# CC1350F128 register map
File version: 1.0
CPU: CM3 1.0, other endian, MPU, FPU, 3 interrupt priority bits
Registers are 32-bit, read-write, reset 0x0 unless marked. A register's access mark holds for its fields unless they carry their own. Offsets are from the block's base; [hi:lo] are bit positions; {n}, {i} and the like mark numbered series.

## AUX_ANAIF — AUX Analog Peripheral Control Module
Base 0x400C9000
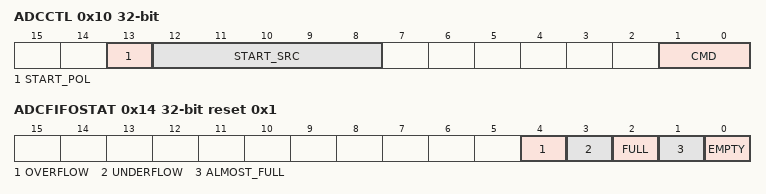
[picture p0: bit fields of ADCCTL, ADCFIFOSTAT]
0x10 ADCCTL — ADC Control Configuration of ADI_4_AUX:ADC0.SMPL_MODE decides if the ADC trigger starts sampling or conversion.
  [13] START_POL — [13:13] Select active polarity for START_SRC event.
    1=FALL (Set ADC trigger on falling edge of event source.); 0=RISE (Set ADC trigger on rising edge of event source.)
  [12:8] START_SRC — [12:8] Select ADC trigger event source from the asynchronous AUX event bus. Set START_SRC to NO_EVENT<n> if you want to trigger the ADC manually through ADCTRIG.START.
    31=ADC_IRQ (AUX_EVCTL:EVSTAT1.ADC_IRQ); 30=MCU_EV (AUX_EVCTL:EVSTAT1.MCU_EV); 29=ACLK_REF (AUX_EVCTL:EVSTAT1.ACLK_REF); {v}=AUXIO{v-13} (AUX_EVCTL:EVSTAT1.AUXIO{v-13}) (v=16..28); 15=AUXIO2 (AUX_EVCTL:EVSTAT0.AUXIO2); 14=AUXIO1 (AUX_EVCTL:EVSTAT0.AUXIO1); 13=AUXIO0 (AUX_EVCTL:EVSTAT0.AUXIO0); 12=AON_PROG_WU (AUX_EVCTL:EVSTAT0.AON_PROG_WU); 11=AON_SW (AUX_EVCTL:EVSTAT0.AON_SW); 10=NO_EVENT1; 9=NO_EVENT0; 6=SMPH_AUTOTAKE_DONE (AUX_EVCTL:EVSTAT0.SMPH_AUTOTAKE_DONE); 5=TIMER1_EV (AUX_EVCTL:EVSTAT0.TIMER1_EV); 4=TIMER0_EV (AUX_EVCTL:EVSTAT0.TIMER0_EV); 3=TDC_DONE (AUX_EVCTL:EVSTAT0.TDC_DONE); 2=AUX_COMPB (AUX_EVCTL:EVSTAT0.AUX_COMPB); 1=AUX_COMPA (AUX_EVCTL:EVSTAT0.AUX_COMPA); 0=RTC_CH2_EV (AUX_EVCTL:EVSTAT0.AON_RTC_CH2)
  [1:0] CMD — [1:0] ADC interface command. Non-enumerated values are not supported. The written value is returned when read.
    3=FLUSH (Flush ADC FIFO. You must set CMD to EN or DIS after flush. System CPU must wait two clock cycles before it sets CMD to EN or DIS.); 1=EN (Enable ADC interface.); 0=DIS (Disable ADC interface.)
0x14 ADCFIFOSTAT reset 0x1 — ADC FIFO Status FIFO can hold up to four ADC samples.
  [4] OVERFLOW ro — [4:4] FIFO overflow flag. 0: FIFO has not overflowed. 1: FIFO has overflowed, this flag is sticky until you flush the FIFO. When the flag is set, the ADC FIFO write pointer is static. It is not possible to add more samples to the ADC FIFO. Flush FIFO to clear the flag.
  [3] UNDERFLOW ro — [3:3] FIFO underflow flag. 0: FIFO has not underflowed. 1: FIFO has underflowed, this flag is sticky until you flush the FIFO. When the flag is set, the ADC FIFO read pointer is static. Read returns the previous sample that was read. Flush FIFO to clear the flag.
  [2] FULL ro — [2:2] FIFO full flag. 0: FIFO is not full, there is less than 4 samples in the FIFO. 1: FIFO is full, there are 4 samples in the FIFO. When the flag is set, it is not possible to add more samples to the ADC FIFO. An attempt to add samples sets the OVERFLOW flag.
  [1] ALMOST_FULL ro — [1:1] FIFO almost full flag. 0: There are less than 3 samples in the FIFO, or the FIFO is full. The FULL flag is also asserted in the latter case. 1: There are 3 samples in the FIFO, there is room for one more sample.
  [0] EMPTY ro — [0:0] FIFO empty flag. 0: FIFO contains one or more samples. 1: FIFO is empty. When the flag is set, read returns the previous sample that was read and sets the UNDERFLOW flag.
0x18 ADCFIFO
  [11:0] DATA — [11:0] FIFO data. Read: Get oldest ADC sample from FIFO. Write: Write dummy sample to FIFO. This is useful for code development when you do not have real ADC samples.
0x1C ADCTRIG — ADC Trigger
  [0] START wo — [0:0] Manual ADC trigger. 0: No effect. 1: Single ADC trigger. To manually trigger the ADC, you must set ADCCTL.START_SRC to NO_EVENT<n> to avoid conflict with event-driven ADC trigger.
0x20 ISRCCTL reset 0x1 — Current Source Control
  [0] RESET_N — [0:0] ISRC reset control. 0: ISRC drives 0 uA. 1: ISRC drives current ADI_4_AUX:ISRC.TRIM to COMPA_IN.

## AUX_SMPH — AUX Semaphore Controller
Base 0x400C8000
{0x0+4i} SMPH{i} reset 0x1 (i=0..7) — Semaphore {i}
  [0] STAT — [0:0] Request or release of semaphore. Request by read: 0: Semaphore not available. 1: Semaphore granted. Release by write: 0: Do not use. 1: Release semaphore.
0x20 AUTOTAKE — Auto Take Sticky Request for Single Semaphore.
  [2:0] SMPH_ID — [2:0] Write the semaphore ID,0x0-0x7, to SMPH_ID to request this semaphore until it is granted. When semaphore SMPH_ID is granted, event AUX_EVCTL:EVSTAT0.AUX_SMPH_AUTOTAKE_DONE becomes 1. The event becomes 0 when software releases the semaphore or writes a new value to SMPH_ID. To avoid corrupted semaphores: - Usage of this functionality must be restricted to one CPU core. - Software must wait until AUX_EVCTL:EVSTAT0.AUX_SMPH_AUTOTAKE_DONE is 1 before it writes a new value to SMPH_ID.
